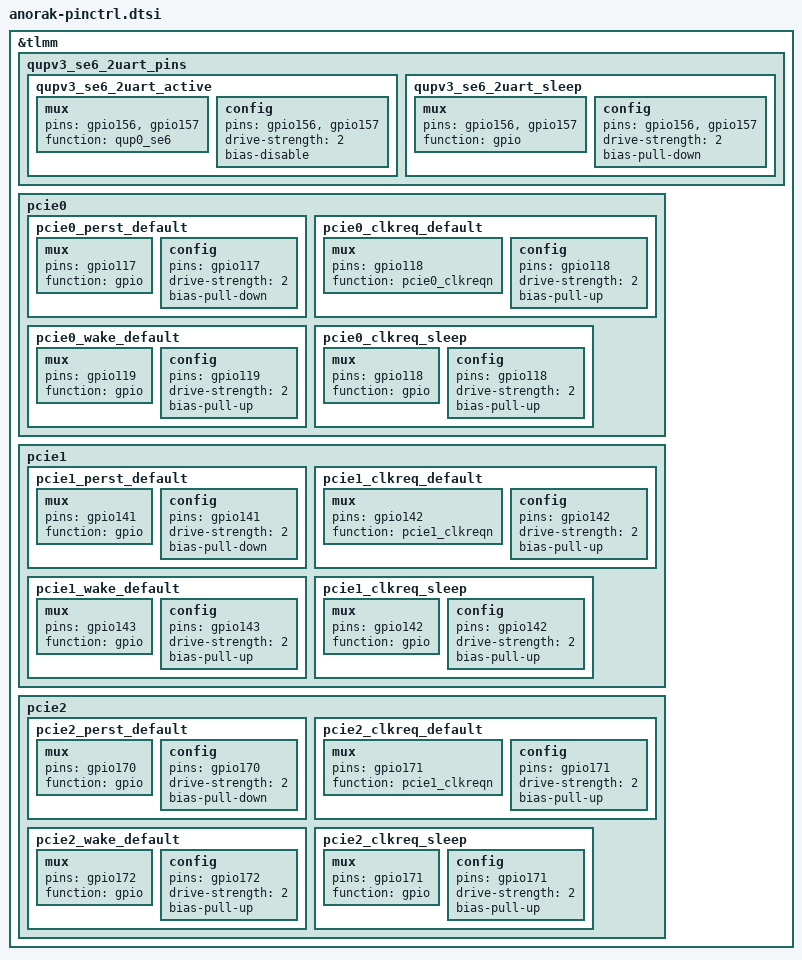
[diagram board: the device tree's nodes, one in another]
&tlmm {
	qupv3_se6_2uart_pins: qupv3_se6_2uart_pins {
		qupv3_se6_2uart_active: qupv3_se6_2uart_active {
			mux {
				pins = "gpio156", "gpio157";
				function = "qup0_se6";
			};

			config {
				pins = "gpio156", "gpio157";
				drive-strength= <2>;
				bias-disable;
			};
		};

		qupv3_se6_2uart_sleep: qupv3_se6_2uart_sleep {
			mux {
				pins = "gpio156", "gpio157";
				function = "gpio";
			};

			config {
				pins = "gpio156", "gpio157";
				drive-strength = <2>;
				bias-pull-down;
			};
		};
	};

	pcie0 {
		pcie0_perst_default: pcie0_perst_default {
			mux {
				pins = "gpio117";
				function = "gpio";
			};

			config {
				pins = "gpio117";
				drive-strength = <2>;
				bias-pull-down;
			};
		};

		pcie0_clkreq_default: pcie0_clkreq_default {
			mux {
				pins = "gpio118";
				function = "pcie0_clkreqn";
			};

			config {
				pins = "gpio118";
				drive-strength = <2>;
				bias-pull-up;
			};
		};

		pcie0_wake_default: pcie0_wake_default {
			mux {
				pins = "gpio119";
				function = "gpio";
			};

			config {
				pins = "gpio119";
				drive-strength = <2>;
				bias-pull-up;
			};
		};

		pcie0_clkreq_sleep: pcie0_clkreq_sleep {
			mux {
				pins = "gpio118";
				function = "gpio";
			};

			config {
				pins = "gpio118";
				drive-strength = <2>;
				bias-pull-up;
			};
		};
	};

	pcie1 {
		pcie1_perst_default: pcie1_perst_default {
			mux {
				pins = "gpio141";
				function = "gpio";
			};

			config {
				pins = "gpio141";
				drive-strength = <2>;
				bias-pull-down;
			};
		};

		pcie1_clkreq_default: pcie1_clkreq_default {
			mux {
				pins = "gpio142";
				function = "pcie1_clkreqn";
			};

			config {
				pins = "gpio142";
				drive-strength = <2>;
				bias-pull-up;
			};
		};

		pcie1_wake_default: pcie1_wake_default {
			mux {
				pins = "gpio143";
				function = "gpio";
			};

			config {
				pins = "gpio143";
				drive-strength = <2>;
				bias-pull-up;
			};
		};

		pcie1_clkreq_sleep: pcie1_clkreq_sleep {
			mux {
				pins = "gpio142";
				function = "gpio";
			};

			config {
				pins = "gpio142";
				drive-strength = <2>;
				bias-pull-up;
			};
		};
	};

	pcie2 {
		pcie2_perst_default: pcie2_perst_default {
			mux {
				pins = "gpio170";
				function = "gpio";
			};

			config {
				pins = "gpio170";
				drive-strength = <2>;
				bias-pull-down;
			};
		};

		pcie2_clkreq_default: pcie2_clkreq_default {
			mux {
				pins = "gpio171";
				function = "pcie1_clkreqn";
			};

			config {
				pins = "gpio171";
				drive-strength = <2>;
				bias-pull-up;
			};
		};

		pcie2_wake_default: pcie2_wake_default {
			mux {
				pins = "gpio172";
				function = "gpio";
			};

			config {
				pins = "gpio172";
				drive-strength = <2>;
				bias-pull-up;
			};
		};

		pcie2_clkreq_sleep: pcie2_clkreq_sleep {
			mux {
				pins = "gpio171";
				function = "gpio";
			};

			config {
				pins = "gpio171";
				drive-strength = <2>;
				bias-pull-up;
			};
		};
	};
};
